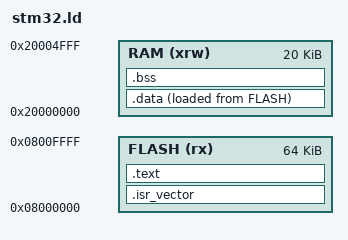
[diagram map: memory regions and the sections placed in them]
ENTRY(Reset_Handler)

MEMORY
{
  FLASH (rx)  : ORIGIN = 0x08000000, LENGTH = 64K
  RAM   (xrw) : ORIGIN = 0x20000000, LENGTH = 20K
}

_estack = ORIGIN(RAM) + LENGTH(RAM);

SECTIONS
{
  .isr_vector :
  {
    . = ALIGN(4);
    KEEP(*(.isr_vector))
    . = ALIGN(4);
  } > FLASH

  .text :
  {
    . = ALIGN(4);
    *(.text*)
    *(.rodata*)
    . = ALIGN(4);
    _etext = .;
  } > FLASH

  _sidata = LOADADDR(.data);

  .data :
  {
    . = ALIGN(4);
    _sdata = .;
    *(.data*)
    . = ALIGN(4);
    _edata = .;
  } > RAM AT> FLASH

  .bss :
  {
    . = ALIGN(4);
    __bss_start__ = .;
    _sbss = .;
    *(.bss*)
    *(COMMON)
    . = ALIGN(4);
    _ebss = .;
    __bss_end__ = .;
  } > RAM

  . = ALIGN(4);
  _end = .;
}
